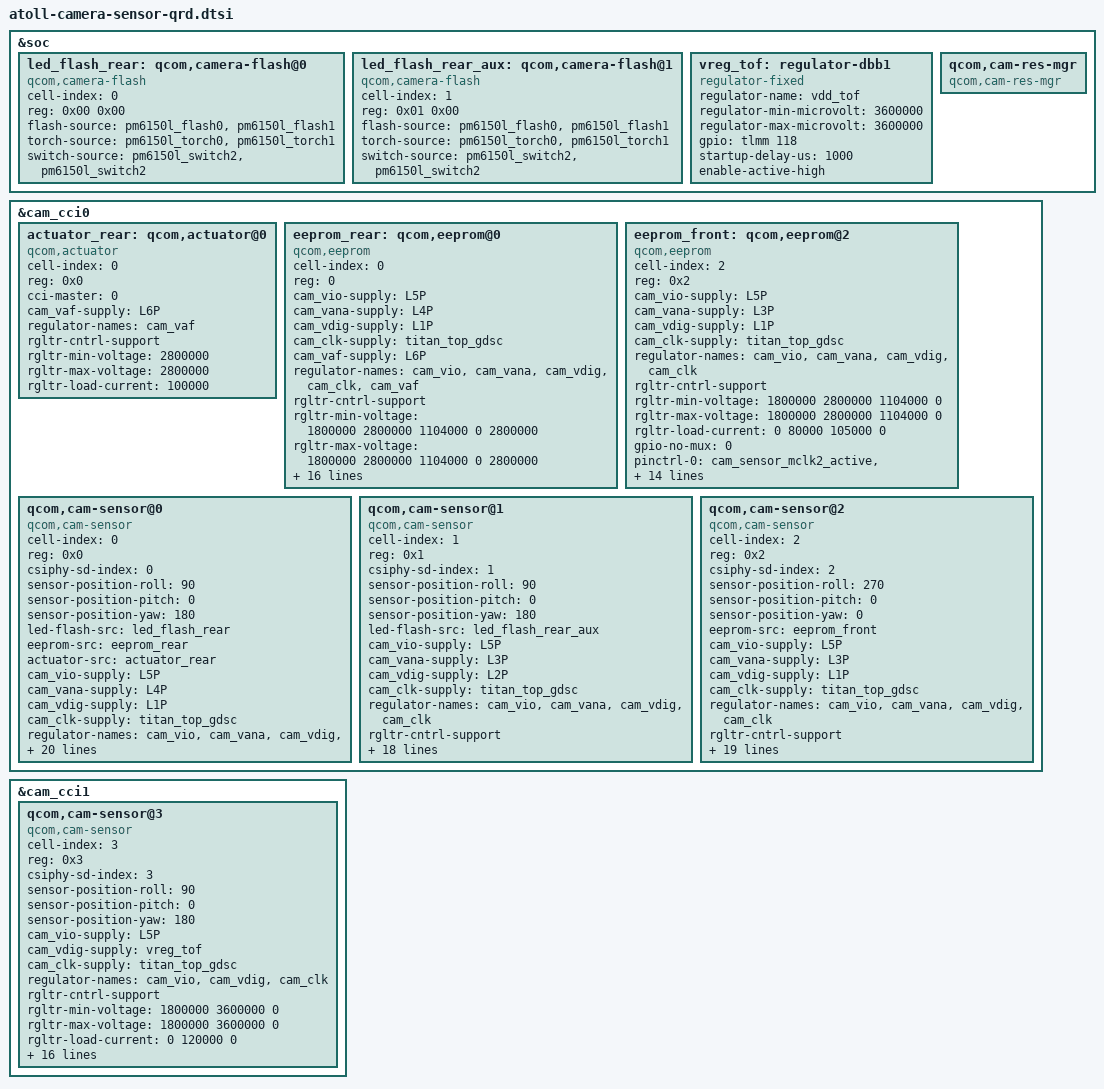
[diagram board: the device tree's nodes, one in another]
/*
 * Copyright (c) 2019, The Linux Foundation. All rights reserved.
 *
 * This program is free software; you can redistribute it and/or modify
 * it under the terms of the GNU General Public License version 2 and
 * only version 2 as published by the Free Software Foundation.
 *
 * This program is distributed in the hope that it will be useful,
 * but WITHOUT ANY WARRANTY; without even the implied warranty of
 * MERCHANTABILITY or FITNESS FOR A PARTICULAR PURPOSE.  See the
 * GNU General Public License for more details.
 */

#include <dt-bindings/clock/qcom,camcc-atoll.h>

&soc {
	led_flash_rear: qcom,camera-flash@0 {
		cell-index = <0>;
		reg = <0x00 0x00>;
		compatible = "qcom,camera-flash";
		flash-source = <&pm6150l_flash0 &pm6150l_flash1>;
		torch-source = <&pm6150l_torch0 &pm6150l_torch1>;
		switch-source = <&pm6150l_switch2 &pm6150l_switch2>;
		status = "ok";
	};

	led_flash_rear_aux: qcom,camera-flash@1 {
		cell-index = <1>;
		reg = <0x01 0x00>;
		compatible = "qcom,camera-flash";
		flash-source = <&pm6150l_flash0 &pm6150l_flash1>;
		torch-source = <&pm6150l_torch0 &pm6150l_torch1>;
		switch-source = <&pm6150l_switch2 &pm6150l_switch2>;
		status = "ok";
	};

	vreg_tof: regulator-dbb1 {
		compatible = "regulator-fixed";
		regulator-name = "vdd_tof";
		regulator-min-microvolt = <3600000>;
		regulator-max-microvolt = <3600000>;
		gpio = <&tlmm 118 GPIO_ACTIVE_HIGH>;
		startup-delay-us = <1000>;
		enable-active-high;
	};

	qcom,cam-res-mgr {
		compatible = "qcom,cam-res-mgr";
		status = "ok";
	};
};

&cam_cci0 {
	actuator_rear: qcom,actuator@0 {
		cell-index = <0>;
		reg = <0x0>;
		compatible = "qcom,actuator";
		cci-master = <0>;
		cam_vaf-supply = <&L6P>;
		regulator-names = "cam_vaf";
		rgltr-cntrl-support;
		rgltr-min-voltage = <2800000>;
		rgltr-max-voltage = <2800000>;
		rgltr-load-current = <100000>;
	};

	eeprom_rear: qcom,eeprom@0 {
		cell-index = <0>;
		reg = <0>;
		compatible = "qcom,eeprom";
		cam_vio-supply = <&L5P>;
		cam_vana-supply = <&L4P>;
		cam_vdig-supply = <&L1P>;
		cam_clk-supply = <&titan_top_gdsc>;
		cam_vaf-supply = <&L6P>;
		regulator-names = "cam_vio", "cam_vana", "cam_vdig",
			"cam_clk", "cam_vaf";
		rgltr-cntrl-support;
		rgltr-min-voltage = <1800000 2800000 1104000 0 2800000>;
		rgltr-max-voltage = <1800000 2800000 1104000 0 2800000>;
		rgltr-load-current = <0 80000 105000 0 100000>;
		gpio-no-mux = <0>;
		pinctrl-names = "cam_default", "cam_suspend";
		pinctrl-0 = <&cam_sensor_mclk0_active
				&cam_sensor_rear_active>;
		pinctrl-1 = <&cam_sensor_mclk0_suspend
				&cam_sensor_rear_suspend>;
		gpios = <&tlmm 13 0>,
			<&tlmm 30 0>;
		gpio-reset = <1>;
		gpio-req-tbl-num = <0 1>;
		gpio-req-tbl-flags = <1 0>;
		gpio-req-tbl-label = "CAMIF_MCLK0",
					"CAM_RESET0";
		sensor-mode = <0>;
		cci-master = <0>;
		status = "ok";
		clocks = <&clock_camcc CAM_CC_MCLK0_CLK>;
		clock-names = "cam_clk";
		clock-cntl-level = "turbo";
		clock-rates = <24000000>;
	};

	eeprom_front: qcom,eeprom@2 {
		cell-index = <2>;
		reg = <0x2>;
		compatible = "qcom,eeprom";
		cam_vio-supply = <&L5P>;
		cam_vana-supply = <&L3P>;
		cam_vdig-supply = <&L1P>;
		cam_clk-supply = <&titan_top_gdsc>;
		regulator-names = "cam_vio", "cam_vana", "cam_vdig",
			"cam_clk";
		rgltr-cntrl-support;
		rgltr-min-voltage = <1800000 2800000 1104000 0>;
		rgltr-max-voltage = <1800000 2800000 1104000 0>;
		rgltr-load-current = <0 80000 105000 0>;
		gpio-no-mux = <0>;
		pinctrl-names = "cam_default", "cam_suspend";
		pinctrl-0 = <&cam_sensor_mclk2_active
				 &cam_sensor_front_active>;
		pinctrl-1 = <&cam_sensor_mclk2_suspend
				 &cam_sensor_front_suspend>;
		gpios = <&tlmm 15 0>,
			<&tlmm 29 0>;
		gpio-reset = <1>;
		gpio-req-tbl-num = <0 1>;
		gpio-req-tbl-flags = <1 0>;
		gpio-req-tbl-label = "CAMIF_MCLK2",
					"CAM_RESET2";
		sensor-mode = <0>;
		cci-device = <0>;
		cci-master = <1>;
		status = "ok";
		clocks = <&clock_camcc CAM_CC_MCLK2_CLK>;
		clock-names = "cam_clk";
		clock-cntl-level = "turbo";
		clock-rates = <24000000>;
	};

	qcom,cam-sensor@0 {
		cell-index = <0>;
		compatible = "qcom,cam-sensor";
		reg = <0x0>;
		csiphy-sd-index = <0>;
		sensor-position-roll = <90>;
		sensor-position-pitch = <0>;
		sensor-position-yaw = <180>;
		led-flash-src = <&led_flash_rear>;
		eeprom-src = <&eeprom_rear>;
		actuator-src = <&actuator_rear>;
		cam_vio-supply = <&L5P>;
		cam_vana-supply = <&L4P>;
		cam_vdig-supply = <&L1P>;
		cam_clk-supply = <&titan_top_gdsc>;
		regulator-names = "cam_vio", "cam_vana", "cam_vdig",
			"cam_clk";
		rgltr-cntrl-support;
		rgltr-min-voltage = <1800000 2800000 1104000 0>;
		rgltr-max-voltage = <1800000 2800000 1104000 0>;
		rgltr-load-current = <0 80000 105000 0>;
		gpio-no-mux = <0>;
		pinctrl-names = "cam_default", "cam_suspend";
		pinctrl-0 = <&cam_sensor_mclk0_active
				&cam_sensor_rear_active>;
		pinctrl-1 = <&cam_sensor_mclk0_suspend
				&cam_sensor_rear_suspend>;
		gpios = <&tlmm 13 0>,
			<&tlmm 30 0>;
		gpio-reset = <1>;
		gpio-req-tbl-num = <0 1>;
		gpio-req-tbl-flags = <1 0>;
		gpio-req-tbl-label = "CAMIF_MCLK0",
					"CAM_RESET0";
		sensor-mode = <0>;
		cci-master = <0>;
		status = "ok";
		clocks = <&clock_camcc CAM_CC_MCLK0_CLK>;
		clock-names = "cam_clk";
		clock-cntl-level = "turbo";
		clock-rates = <24000000>;
	};

	qcom,cam-sensor@1 {
		cell-index = <1>;
		compatible = "qcom,cam-sensor";
		reg = <0x1>;
		csiphy-sd-index = <1>;
		sensor-position-roll = <90>;
		sensor-position-pitch = <0>;
		sensor-position-yaw = <180>;
		led-flash-src = <&led_flash_rear_aux>;
		cam_vio-supply = <&L5P>;
		cam_vana-supply = <&L3P>;
		cam_vdig-supply = <&L2P>;
		cam_clk-supply = <&titan_top_gdsc>;
		regulator-names = "cam_vio", "cam_vana", "cam_vdig",
			"cam_clk";
		rgltr-cntrl-support;
		rgltr-min-voltage = <1800000 2800000 1104000 0>;
		rgltr-max-voltage = <1800000 2800000 1104000 0>;
		rgltr-load-current = <0 80000 105000 0>;
		gpio-no-mux = <0>;
		pinctrl-names = "cam_default", "cam_suspend";
		pinctrl-0 = <&cam_sensor_mclk1_active
				&cam_sensor_rear2_active>;
		pinctrl-1 = <&cam_sensor_mclk1_suspend
				&cam_sensor_rear2_suspend>;
		gpios = <&tlmm 14 0>,
			<&tlmm 25 0>;
		gpio-reset = <1>;
		gpio-req-tbl-num = <0 1>;
		gpio-req-tbl-flags = <1 0>;
		gpio-req-tbl-label = "CAMIF_MCLK1",
					"CAM_RESET1";
		sensor-mode = <0>;
		cci-master = <1>;
		status = "ok";
		clocks = <&clock_camcc CAM_CC_MCLK1_CLK>;
		clock-names = "cam_clk";
		clock-cntl-level = "turbo";
		clock-rates = <24000000>;
	};

	qcom,cam-sensor@2 {
		cell-index = <2>;
		compatible = "qcom,cam-sensor";
		reg = <0x2>;
		csiphy-sd-index = <2>;
		sensor-position-roll = <270>;
		sensor-position-pitch = <0>;
		sensor-position-yaw = <0>;
		eeprom-src = <&eeprom_front>;
		cam_vio-supply = <&L5P>;
		cam_vana-supply = <&L3P>;
		cam_vdig-supply = <&L1P>;
		cam_clk-supply = <&titan_top_gdsc>;
		regulator-names = "cam_vio", "cam_vana", "cam_vdig",
			"cam_clk";
		rgltr-cntrl-support;
		rgltr-min-voltage = <1800000 2800000 1104000 0>;
		rgltr-max-voltage = <1800000 2800000 1104000 0>;
		rgltr-load-current = <0 80000 105000 0>;
		gpio-no-mux = <0>;
		pinctrl-names = "cam_default", "cam_suspend";
		pinctrl-0 = <&cam_sensor_mclk2_active
				 &cam_sensor_front_active>;
		pinctrl-1 = <&cam_sensor_mclk2_suspend
				 &cam_sensor_front_suspend>;
		gpios = <&tlmm 15 0>,
			<&tlmm 29 0>;
		gpio-reset = <1>;
		gpio-req-tbl-num = <0 1>;
		gpio-req-tbl-flags = <1 0>;
		gpio-req-tbl-label = "CAMIF_MCLK2",
					"CAM_RESET2";
		sensor-mode = <0>;
		cci-device = <0>;
		cci-master = <1>;
		status = "ok";
		clocks = <&clock_camcc CAM_CC_MCLK2_CLK>;
		clock-names = "cam_clk";
		clock-cntl-level = "turbo";
		clock-rates = <24000000>;
	};
};

&cam_cci1 {
	qcom,cam-sensor@3 {
		cell-index = <3>;
		compatible = "qcom,cam-sensor";
		reg = <0x3>;
		csiphy-sd-index = <3>;
		sensor-position-roll = <90>;
		sensor-position-pitch = <0>;
		sensor-position-yaw = <180>;
		cam_vio-supply = <&L5P>;
		cam_vdig-supply = <&vreg_tof>;
		cam_clk-supply = <&titan_top_gdsc>;
		regulator-names = "cam_vio", "cam_vdig",
			"cam_clk";
		rgltr-cntrl-support;
		rgltr-min-voltage = <1800000 3600000 0>;
		rgltr-max-voltage = <1800000 3600000 0>;
		rgltr-load-current = <0 120000 0>;
		gpio-no-mux = <0>;
		pinctrl-names = "cam_default", "cam_suspend";
		pinctrl-0 = <&cam_sensor_mclk3_active
				 &cam_sensor_tof_active>;
		pinctrl-1 = <&cam_sensor_mclk3_suspend
				 &cam_sensor_tof_suspend>;
		gpios = <&tlmm 16 0>,
			<&tlmm 24 0>;
		gpio-reset = <1>;
		gpio-req-tbl-num = <0 1>;
		gpio-req-tbl-flags = <1 0>;
		gpio-req-tbl-label = "CAMIF_MCLK3",
					"CAM_RESET3";
		sensor-mode = <0>;
		cci-device = <1>;
		cci-master = <0>;
		status = "ok";
		clocks = <&clock_camcc CAM_CC_MCLK3_CLK>;
		clock-names = "cam_clk";
		clock-cntl-level = "turbo";
		clock-rates = <24000000>;
	};
};
